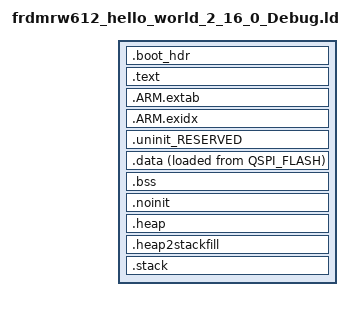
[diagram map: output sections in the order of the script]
/*
 * GENERATED FILE - DO NOT EDIT
 * Copyright 2008-2013 Code Red Technologies Ltd,
 * Copyright 2013-2024 NXP
 * Generated linker script file for RW612
 * Created from linkscript.ldt by FMCreateLinkLibraries
 * Using Freemarker v2.3.30
 * MCUXpresso IDE v11.9.1 [Build 2170] [2024-04-19] on Aug 6, 2024, 4:48:49 PM
 */

INCLUDE "frdmrw612_hello_world_2_16_0_Debug_library.ld"
INCLUDE "frdmrw612_hello_world_2_16_0_Debug_memory.ld"

ENTRY(ResetISR)

SECTIONS
{
     /* Offset .text by 0x1000 bytes, which whill be added by the image tool*/
    .boot_hdr : ALIGN(4)
    {
        FILL(0xFF)
        . = 0x400;
        __FLASH_BASE = .;
        KEEP(*(.flash_conf))
        . = 0x1000;
    } > QSPI_FLASH

    /* MAIN TEXT SECTION */
    .text : ALIGN(4)
    {
        FILL(0xff)
        __vectors_start__ = ABSOLUTE(.) ;
        KEEP(*(.isr_vector))
        /* Global Section Table */
        . = ALIGN(4) ;
        __section_table_start = .;
        __data_section_table = .;
        LONG(LOADADDR(.data));
        LONG(    ADDR(.data));
        LONG(  SIZEOF(.data));
        __data_section_table_end = .;
        __bss_section_table = .;
        LONG(    ADDR(.bss));
        LONG(  SIZEOF(.bss));
        __bss_section_table_end = .;
        __section_table_end = . ;
        /* End of Global Section Table */

        *(.after_vectors*)

       *(.text*)
       *(.rodata .rodata.* .constdata .constdata.*)
       . = ALIGN(4);
    } > QSPI_FLASH
    /*
     * for exception handling/unwind - some Newlib functions (in common
     * with C++ and STDC++) use this.
     */
    .ARM.extab : ALIGN(4)
    {
        *(.ARM.extab* .gnu.linkonce.armextab.*)
    } > QSPI_FLASH

    .ARM.exidx : ALIGN(4)
    {
        __exidx_start = .;
        *(.ARM.exidx* .gnu.linkonce.armexidx.*)
        __exidx_end = .;
    } > QSPI_FLASH
 
    _etext = .;
        
    /* MAIN DATA SECTION */
    .uninit_RESERVED (NOLOAD) : ALIGN(4)
    {
        _start_uninit_RESERVED = .;
        KEEP(*(.bss.$RESERVED*))
       . = ALIGN(4) ;
        _end_uninit_RESERVED = .;
    } > SRAM AT> SRAM

    /* Main DATA section (SRAM) */
    .data : ALIGN(4)
    {
       FILL(0xff)
       _data = . ;
       PROVIDE(__start_data_RAM = .) ;
       PROVIDE(__start_data_SRAM = .) ;
       *(vtable)
       *(.ramfunc*)
       KEEP(*(CodeQuickAccess))
       KEEP(*(DataQuickAccess))
       *(RamFunction)
       *(.data*)
       . = ALIGN(4) ;
       _edata = . ;
       PROVIDE(__end_data_RAM = .) ;
       PROVIDE(__end_data_SRAM = .) ;
    } > SRAM AT>QSPI_FLASH

    /* MAIN BSS SECTION */
    .bss (NOLOAD) : ALIGN(4)
    {
        _bss = .;
        PROVIDE(__start_bss_RAM = .) ;
        PROVIDE(__start_bss_SRAM = .) ;
        *(.bss*)
        *(COMMON)
        . = ALIGN(4) ;
        _ebss = .;
        PROVIDE(__end_bss_RAM = .) ;
        PROVIDE(__end_bss_SRAM = .) ;
        PROVIDE(end = .);
    } > SRAM AT> SRAM

    /* DEFAULT NOINIT SECTION */
    .noinit (NOLOAD): ALIGN(4)
    {
        _noinit = .;
        PROVIDE(__start_noinit_RAM = .) ;
        PROVIDE(__start_noinit_SRAM = .) ;
        *(.noinit*)
         . = ALIGN(4) ;
        _end_noinit = .;
       PROVIDE(__end_noinit_RAM = .) ;
       PROVIDE(__end_noinit_SRAM = .) ;        
    } > SRAM AT> SRAM

    /* Reserve and place Heap within memory map */
    _HeapSize = 0x1000;
    .heap (NOLOAD) :  ALIGN(4)
    {
        _pvHeapStart = .;
        . += _HeapSize;
        . = ALIGN(4);
        _pvHeapLimit = .;
    } > SRAM

     _StackSize = 0x1000;
     /* Reserve space in memory for Stack */
    .heap2stackfill (NOLOAD) :
    {
        . += _StackSize;
    } > SRAM
    /* Locate actual Stack in memory map */
    .stack ORIGIN(SRAM) + LENGTH(SRAM) - _StackSize - 0 (NOLOAD) :  ALIGN(4)
    {
        _vStackBase = .;
        . = ALIGN(4);
        _vStackTop = . + _StackSize;
    } > SRAM

    /* Provide basic symbols giving location and size of main text
     * block, including initial values of RW data sections. Note that
     * these will need extending to give a complete picture with
     * complex images (e.g multiple Flash banks).
     */
    _image_start = LOADADDR(.text);
    _image_end = LOADADDR(.data) + SIZEOF(.data);
    _image_size = _image_end - _image_start;
}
